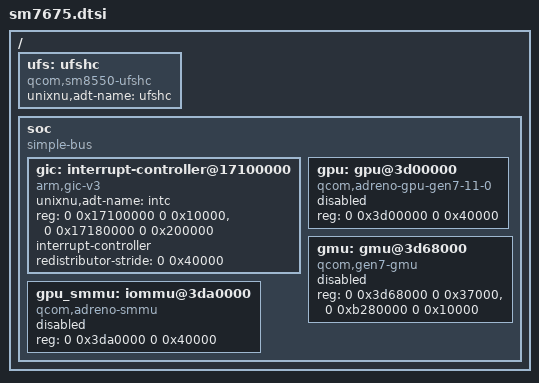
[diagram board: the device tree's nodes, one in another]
// SPDX-License-Identifier: BSD-3-Clause
// Shared Qualcomm SM7675 (cliffs) resources: the SoC controllers the common
// ADT generator exports. Board memory, CPU selection and peripherals live in
// the device repository's dts/. Derived from the uke vendor_boot device tree
// and the Xiaomi kernel sources at 5712080a.
/ {
    // UFS at 0x1d84000 lies below the arm-io window, so the node exists
    // only for class matching; the driver takes its physical windows from
    // the board's GccUfs.h.
    ufs: ufshc {
        compatible = "qcom,sm8550-ufshc";
        unixnu,adt-name = "ufshc";
    };

    soc {
        compatible = "simple-bus";
        #address-cells = <2>;
        #size-cells = <2>;
        ranges;

        gic: interrupt-controller@17100000 {
            compatible = "arm,gic-v3";
            unixnu,adt-name = "intc";
            reg = <0 0x17100000 0 0x10000>, <0 0x17180000 0 0x200000>;
            #interrupt-cells = <4>;
            #address-cells = <0>;
            interrupt-controller;
            redistributor-stride = <0 0x40000>;
        };

        gpu: gpu@3d00000 {
            compatible = "qcom,adreno-gpu-gen7-11-0", "qcom,kgsl-3d0";
            reg = <0 0x3d00000 0 0x40000>;
            status = "disabled";
        };

        gmu: gmu@3d68000 {
            compatible = "qcom,gen7-gmu";
            reg = <0 0x3d68000 0 0x37000>, <0 0xb280000 0 0x10000>;
            reg-names = "gmu", "gmu_pdc";
            status = "disabled";
        };

        gpu_smmu: iommu@3da0000 {
            compatible = "qcom,adreno-smmu", "arm,mmu-500";
            reg = <0 0x3da0000 0 0x40000>;
            #iommu-cells = <2>;
            status = "disabled";
        };
    };
};
